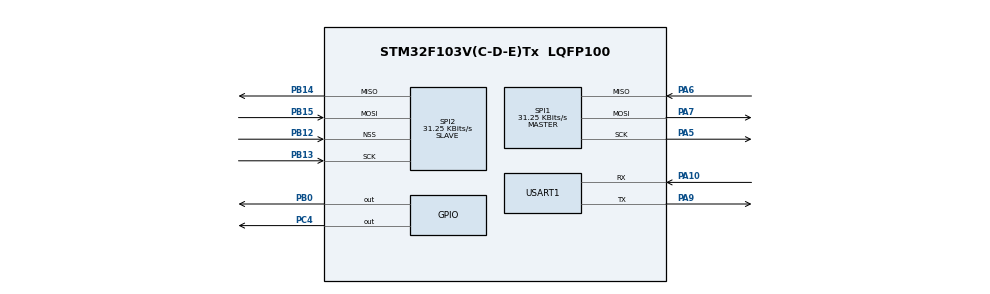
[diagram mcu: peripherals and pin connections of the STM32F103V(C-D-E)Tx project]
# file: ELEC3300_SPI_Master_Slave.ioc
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Mcu.Family=STM32F1
Mcu.Name=STM32F103V(C-D-E)Tx
Mcu.Package=LQFP100
NVIC.PriorityGroup=NVIC_PRIORITYGROUP_4
NVIC.SPI1_IRQn=true\:0\:0\:false\:false\:true\:true\:true
NVIC.SPI2_IRQn=true\:0\:0\:false\:false\:true\:true\:true
PA10.Mode=Asynchronous
PA10.Signal=USART1_RX
PA13.Mode=Serial_Wire
PA13.Signal=SYS_JTMS-SWDIO
PA14.Mode=Serial_Wire
PA14.Signal=SYS_JTCK-SWCLK
PA5.Mode=Full_Duplex_Master
PA5.Signal=SPI1_SCK
PA6.Mode=Full_Duplex_Master
PA6.Signal=SPI1_MISO
PA7.Mode=Full_Duplex_Master
PA7.Signal=SPI1_MOSI
PA9.Mode=Asynchronous
PA9.Signal=USART1_TX
PB0.PinState=GPIO_PIN_RESET
PB0.Signal=GPIO_Output
PB12.Mode=NSS_Signal_Hard_Input
PB12.Signal=SPI2_NSS
PB13.Mode=Full_Duplex_Slave
PB13.Signal=SPI2_SCK
PB14.Mode=Full_Duplex_Slave
PB14.Signal=SPI2_MISO
PB15.Mode=Full_Duplex_Slave
PB15.Signal=SPI2_MOSI
PC4.PinState=GPIO_PIN_RESET
PC4.Signal=GPIO_Output
ProjectManager.HeapSize=0x200
ProjectManager.StackSize=0x400
ProjectManager.TargetToolchain=MDK-ARM V5.27
RCC.APB1Freq_Value=8000000
RCC.APB2Freq_Value=8000000
SPI1.BaudRatePrescaler=SPI_BAUDRATEPRESCALER_256
SPI1.CalculateBaudRate=31.25 KBits/s
SPI1.Direction=SPI_DIRECTION_2LINES
SPI1.Mode=SPI_MODE_MASTER
SPI1.VirtualType=VM_MASTER
SPI2.BaudRatePrescaler=SPI_BAUDRATEPRESCALER_256
SPI2.CalculateBaudRate=31.25 KBits/s
SPI2.Direction=SPI_DIRECTION_2LINES
SPI2.Mode=SPI_MODE_SLAVE
SPI2.VirtualNSS=VM_NSSHARD
SPI2.VirtualType=VM_SLAVE
USART1.VirtualMode=VM_ASYNC
board=custom

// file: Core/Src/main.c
/* USER CODE BEGIN Header */
/**
  ******************************************************************************
  * @file           : main.c
  * @brief          : Main program body
  ******************************************************************************
  * @attention
  *
  * <h2><center>&copy; Copyright (c) 2023 STMicroelectronics.
  * All rights reserved.</center></h2>
  *
  * This software component is licensed by ST under BSD 3-Clause license,
  * the "License"; You may not use this file except in compliance with the
  * License. You may obtain a copy of the License at:
  *                        opensource.org/licenses/BSD-3-Clause
  *
  ******************************************************************************
  */
/* USER CODE END Header */
#include "main.h"

/* USER CODE BEGIN Includes */
char data_tx[10] = {65,66,67,68,69,70,71,72,73,74};
char data_rx[10];
/* USER CODE END Includes */

SPI_HandleTypeDef hspi1;
SPI_HandleTypeDef hspi2;

UART_HandleTypeDef huart1;

void SystemClock_Config(void);
static void MX_GPIO_Init(void);
static void MX_SPI1_Init(void);
static void MX_SPI2_Init(void);
static void MX_USART1_UART_Init(void);

/* USER CODE BEGIN 0 */
void HAL_SPI_RxCpltCallback(SPI_HandleTypeDef *hspi){
	if(hspi->Instance==SPI2){
		HAL_SPI_Receive_IT(&hspi2,(uint8_t*)data_rx,10);
	}
}
/* USER CODE END 0 */

int main(void)
{

  /* MCU Configuration--------------------------------------------------------*/

  /* Reset of all peripherals, Initializes the Flash interface and the Systick. */
  HAL_Init();

  /* Configure the system clock */
  SystemClock_Config();

  /* Initialize all configured peripherals */
  MX_GPIO_Init();
  MX_SPI1_Init();
  MX_SPI2_Init();
  MX_USART1_UART_Init();
  /* USER CODE BEGIN 2 */
HAL_SPI_Receive_IT(&hspi2,(uint8_t*)data_rx,10);
  /* USER CODE END 2 */

  /* Infinite loop */
  while (1)
  {

    /* USER CODE BEGIN 3 */
		  HAL_GPIO_TogglePin(GPIOB, GPIO_PIN_0);
		  HAL_Delay(100);
		HAL_SPI_Transmit(&hspi1,(uint8_t*)data_tx,10,100);
		while(HAL_SPI_GetState(&hspi1)!=HAL_SPI_STATE_READY);

		// UART Transmit
		HAL_UART_Transmit(&huart1,(uint8_t*)&data_rx,sizeof(data_rx),5000);
  }
  /* USER CODE END 3 */
}

void SystemClock_Config(void)
{
  RCC_OscInitTypeDef RCC_OscInitStruct = {0};
  RCC_ClkInitTypeDef RCC_ClkInitStruct = {0};

  /** Initializes the RCC Oscillators according to the specified parameters
  * in the RCC_OscInitTypeDef structure.
  */
  RCC_OscInitStruct.OscillatorType = RCC_OSCILLATORTYPE_HSI;
  RCC_OscInitStruct.HSIState = RCC_HSI_ON;
  RCC_OscInitStruct.HSICalibrationValue = RCC_HSICALIBRATION_DEFAULT;
  RCC_OscInitStruct.PLL.PLLState = RCC_PLL_NONE;
  if (HAL_RCC_OscConfig(&RCC_OscInitStruct) != HAL_OK)
  {
    Error_Handler();
  }
  /** Initializes the CPU, AHB and APB buses clocks
  */
  RCC_ClkInitStruct.ClockType = RCC_CLOCKTYPE_HCLK|RCC_CLOCKTYPE_SYSCLK
                              |RCC_CLOCKTYPE_PCLK1|RCC_CLOCKTYPE_PCLK2;
  RCC_ClkInitStruct.SYSCLKSource = RCC_SYSCLKSOURCE_HSI;
  RCC_ClkInitStruct.AHBCLKDivider = RCC_SYSCLK_DIV1;
  RCC_ClkInitStruct.APB1CLKDivider = RCC_HCLK_DIV1;
  RCC_ClkInitStruct.APB2CLKDivider = RCC_HCLK_DIV1;

  if (HAL_RCC_ClockConfig(&RCC_ClkInitStruct, FLASH_LATENCY_0) != HAL_OK)
  {
    Error_Handler();
  }
}

static void MX_SPI1_Init(void)
{

  /* SPI1 parameter configuration*/
  hspi1.Instance = SPI1;
  hspi1.Init.Mode = SPI_MODE_MASTER;
  hspi1.Init.Direction = SPI_DIRECTION_2LINES;
  hspi1.Init.DataSize = SPI_DATASIZE_8BIT;
  hspi1.Init.CLKPolarity = SPI_POLARITY_LOW;
  hspi1.Init.CLKPhase = SPI_PHASE_1EDGE;
  hspi1.Init.NSS = SPI_NSS_SOFT;
  hspi1.Init.BaudRatePrescaler = SPI_BAUDRATEPRESCALER_256;
  hspi1.Init.FirstBit = SPI_FIRSTBIT_MSB;
  hspi1.Init.TIMode = SPI_TIMODE_DISABLE;
  hspi1.Init.CRCCalculation = SPI_CRCCALCULATION_DISABLE;
  hspi1.Init.CRCPolynomial = 10;
  if (HAL_SPI_Init(&hspi1) != HAL_OK)
  {
    Error_Handler();
  }

}

static void MX_SPI2_Init(void)
{

  /* SPI2 parameter configuration*/
  hspi2.Instance = SPI2;
  hspi2.Init.Mode = SPI_MODE_SLAVE;
  hspi2.Init.Direction = SPI_DIRECTION_2LINES;
  hspi2.Init.DataSize = SPI_DATASIZE_8BIT;
  hspi2.Init.CLKPolarity = SPI_POLARITY_LOW;
  hspi2.Init.CLKPhase = SPI_PHASE_1EDGE;
  hspi2.Init.NSS = SPI_NSS_HARD_INPUT;
  hspi2.Init.BaudRatePrescaler = SPI_BAUDRATEPRESCALER_256;
  hspi2.Init.FirstBit = SPI_FIRSTBIT_MSB;
  hspi2.Init.TIMode = SPI_TIMODE_DISABLE;
  hspi2.Init.CRCCalculation = SPI_CRCCALCULATION_DISABLE;
  hspi2.Init.CRCPolynomial = 10;
  if (HAL_SPI_Init(&hspi2) != HAL_OK)
  {
    Error_Handler();
  }

}

static void MX_USART1_UART_Init(void)
{

  huart1.Instance = USART1;
  huart1.Init.BaudRate = 115200;
  huart1.Init.WordLength = UART_WORDLENGTH_8B;
  huart1.Init.StopBits = UART_STOPBITS_1;
  huart1.Init.Parity = UART_PARITY_NONE;
  huart1.Init.Mode = UART_MODE_TX_RX;
  huart1.Init.HwFlowCtl = UART_HWCONTROL_NONE;
  huart1.Init.OverSampling = UART_OVERSAMPLING_16;
  if (HAL_UART_Init(&huart1) != HAL_OK)
  {
    Error_Handler();
  }

}

static void MX_GPIO_Init(void)
{
  GPIO_InitTypeDef GPIO_InitStruct = {0};

  /* GPIO Ports Clock Enable */
  __HAL_RCC_GPIOA_CLK_ENABLE();
  __HAL_RCC_GPIOC_CLK_ENABLE();
  __HAL_RCC_GPIOB_CLK_ENABLE();

  /*Configure GPIO pin Output Level */
  HAL_GPIO_WritePin(GPIOC, GPIO_PIN_4, GPIO_PIN_RESET);

  /*Configure GPIO pin Output Level */
  HAL_GPIO_WritePin(GPIOB, GPIO_PIN_0, GPIO_PIN_RESET);

  /*Configure GPIO pin : PC4 */
  GPIO_InitStruct.Pin = GPIO_PIN_4;
  GPIO_InitStruct.Mode = GPIO_MODE_OUTPUT_PP;
  GPIO_InitStruct.Pull = GPIO_NOPULL;
  GPIO_InitStruct.Speed = GPIO_SPEED_FREQ_LOW;
  HAL_GPIO_Init(GPIOC, &GPIO_InitStruct);

  /*Configure GPIO pin : PB0 */
  GPIO_InitStruct.Pin = GPIO_PIN_0;
  GPIO_InitStruct.Mode = GPIO_MODE_OUTPUT_PP;
  GPIO_InitStruct.Pull = GPIO_NOPULL;
  GPIO_InitStruct.Speed = GPIO_SPEED_FREQ_LOW;
  HAL_GPIO_Init(GPIOB, &GPIO_InitStruct);

}

void Error_Handler(void)
{
  __disable_irq();
  while (1)
  {
  }
}

/************************ (C) COPYRIGHT STMicroelectronics *****END OF FILE****/
